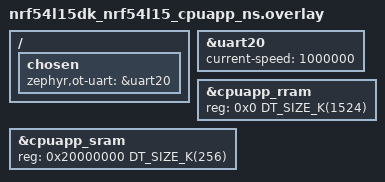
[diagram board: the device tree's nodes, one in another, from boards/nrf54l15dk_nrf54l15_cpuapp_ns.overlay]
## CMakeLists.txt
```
#
# Copyright (c) 2020 Nordic Semiconductor ASA
#
# SPDX-License-Identifier: LicenseRef-Nordic-5-Clause
#

cmake_minimum_required(VERSION 3.20.0)

set(OT_NCP_VENDOR_HOOK_SOURCE_DIR ${CMAKE_CURRENT_SOURCE_DIR})

find_package(Zephyr REQUIRED HINTS $ENV{ZEPHYR_BASE})

project(openthread_coprocessor)

# NORDIC SDK APP START
target_sources(app PRIVATE src/main.c src/nrf_802154_radio_wrapper.c)
target_sources_ifdef(CONFIG_RCP_SAMPLE_HCI app PRIVATE src/rcp_hci.c)
target_sources_ifdef(CONFIG_RCP_SAMPLE_UART app PRIVATE src/rcp_uart.c)
# NORDIC SDK APP END
```

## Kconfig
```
#
# Copyright (c) 2023 Nordic Semiconductor ASA
#
# SPDX-License-Identifier: LicenseRef-Nordic-5-Clause
#

menu "Zephyr Kernel"
source "Kconfig.zephyr"
endmenu

module = OT_COPROCESSOR
module-str = ot_coprocessor
source "${ZEPHYR_BASE}/subsys/logging/Kconfig.template.log_config"

config RCP_SAMPLE_HCI
	bool "Enable  Bluetooth HCI USB support for the coprocessor sample"
	select EXPERIMENTAL

config RCP_SAMPLE_UART
	bool "Enable UART transport mode for Thread RCP"
	default y
	depends on !RCP_SAMPLE_HCI
```

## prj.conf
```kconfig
#
# Copyright (c) 2020 Nordic Semiconductor
#
# SPDX-License-Identifier: LicenseRef-Nordic-5-Clause
#

# Enable OpenThread
CONFIG_OPENTHREAD=y

# Set OpenThread NCP architecture
CONFIG_OPENTHREAD_COPROCESSOR=y
CONFIG_OPENTHREAD_COPROCESSOR_RCP=y
CONFIG_RCP_SAMPLE_UART=y

# Nordic feature set
CONFIG_OPENTHREAD_NORDIC_LIBRARY_RCP=y

# Increase Settings storage size
CONFIG_PM_PARTITION_SIZE_SETTINGS_STORAGE=0x8000

# Disable RTT
CONFIG_USE_SEGGER_RTT=n

# Disable GPIO
CONFIG_GPIO=n

# Disable APPROTECT for development
CONFIG_NRF_APPROTECT_USE_UICR=n
# CONFIG_NRF_APPROTECT_LOCK is not set
```

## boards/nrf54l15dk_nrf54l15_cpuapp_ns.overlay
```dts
/* Copyright (c) 2024 Nordic Semiconductor ASA
 *
 * SPDX-License-Identifier: LicenseRef-Nordic-5-Clause
 */

&uart20 {
	current-speed = <1000000>;
	status = "okay";
	/delete-property/ hw-flow-control;
};

/ {
	chosen {
		zephyr,ot-uart = &uart20;
	};
};

// restore full RRAM and SRAM space - by default some parts are dedicated to FLPR
&cpuapp_rram {
	reg = <0x0 DT_SIZE_K(1524)>;
};

&cpuapp_sram {
	reg = <0x20000000 DT_SIZE_K(256)>;
	ranges = <0x0 0x20000000 DT_SIZE_K(256)>;
};
```

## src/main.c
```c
/*
 * Copyright (c) 2023 Nordic Semiconductor ASA
 *
 * SPDX-License-Identifier: LicenseRef-Nordic-5-Clause
 */
#include <zephyr/kernel.h>
#include <zephyr/logging/log.h>

#if defined(CONFIG_RCP_SAMPLE_HCI)
#include "rcp_hci.h"
#elif defined(CONFIG_RCP_SAMPLE_UART)
#include "rcp_uart.h"
#endif

LOG_MODULE_REGISTER(coprocessor_sample, CONFIG_OT_COPROCESSOR_LOG_LEVEL);

#define WELCOME_TEXT                                                           \
	"\n\r"                                                                 \
	"\n\r"                                                                 \
	"=========================================================\n\r"        \
	"OpenThread Coprocessor application is now running on NCS.\n\r"        \
	"=========================================================\n\r"

int main(void)
{
	LOG_INF(WELCOME_TEXT);

#if defined(CONFIG_RCP_SAMPLE_HCI)
	run_hci();
#elif defined(CONFIG_RCP_SAMPLE_UART)
	run_uart();
#endif

	return 0;
}
```

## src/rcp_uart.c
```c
/*
 * Copyright (c) 2024 Nordic Semiconductor ASA
 *
 * SPDX-License-Identifier: LicenseRef-Nordic-5-Clause
 */

#include "rcp_uart.h"

#include <zephyr/device.h>
#include <zephyr/devicetree.h>
#include <zephyr/drivers/uart.h>
#include <zephyr/kernel.h>
#include <zephyr/logging/log.h>

LOG_MODULE_REGISTER(rcp_uart_module, CONFIG_OT_COPROCESSOR_LOG_LEVEL);

static const struct device *const ot_uart = DEVICE_DT_GET(DT_CHOSEN(zephyr_ot_uart));

void run_uart(void)
{
	__ASSERT(ot_uart, "OpenThread UART device is NULL");

	if (!device_is_ready(ot_uart)) {
		LOG_ERR("OpenThread UART %s is not ready", ot_uart->name);
		return;
	}

#if DT_NODE_HAS_PROP(DT_CHOSEN(zephyr_ot_uart), current_speed)
	LOG_INF("RCP UART mode enabled: dev=%s speed=%d", ot_uart->name,
		DT_PROP(DT_CHOSEN(zephyr_ot_uart), current_speed));
#else
	LOG_INF("RCP UART mode enabled: dev=%s", ot_uart->name);
#endif

	/* OpenThread handles Spinel traffic on zephyr,ot-uart in its own context. */
	while (1) {
		k_sleep(K_FOREVER);
	}
}
```

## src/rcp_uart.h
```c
/*
 * Copyright (c) 2024 Nordic Semiconductor ASA
 *
 * SPDX-License-Identifier: LicenseRef-Nordic-5-Clause
 */

#ifndef RCP_UART_H_
#define RCP_UART_H_

void run_uart(void);

#endif /* RCP_UART_H_ */
```
